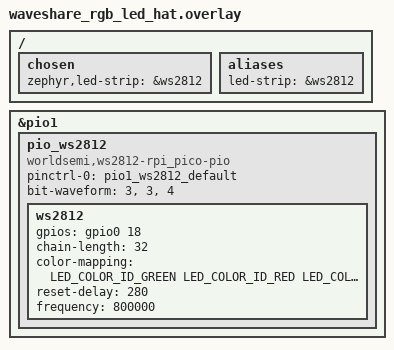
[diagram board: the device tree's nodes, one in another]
#include "waveshare_rgb_led_hat-pinctrl.dtsi"

#include <zephyr/dt-bindings/led/led.h>
#include <zephyr/dt-bindings/gpio/gpio.h>

/ {
    chosen {
        zephyr,led-strip = &ws2812;
    };

    aliases {
        led-strip = &ws2812;
    };
};

&pio1 {
    status = "okay";

    pio_ws2812 {
        compatible = "worldsemi,ws2812-rpi_pico-pio";
        status = "okay";

        pinctrl-0 = <&pio1_ws2812_default>;
        pinctrl-names = "default";

        bit-waveform = <3>, <3>, <4>;

        ws2812: ws2812 {
            status = "okay";

            gpios = <&gpio0 18 GPIO_ACTIVE_HIGH>;

            chain-length = <32>;

            color-mapping = <LED_COLOR_ID_GREEN
                             LED_COLOR_ID_RED
                             LED_COLOR_ID_BLUE>;

            reset-delay = <280>;
            frequency = <800000>;
        };
    };
};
